# GD32F3x0 register map
File version: 1.0
CPU: CM4 r2p1, little endian, MPU, no FPU, 4 interrupt priority bits
Registers are 32-bit, read-write, reset 0x0 unless marked. A register's access mark holds for its fields unless they carry their own. Offsets are from the block's base; [hi:lo] are bit positions.

## CEC — HDMI-CEC controller
Base 0x40007800
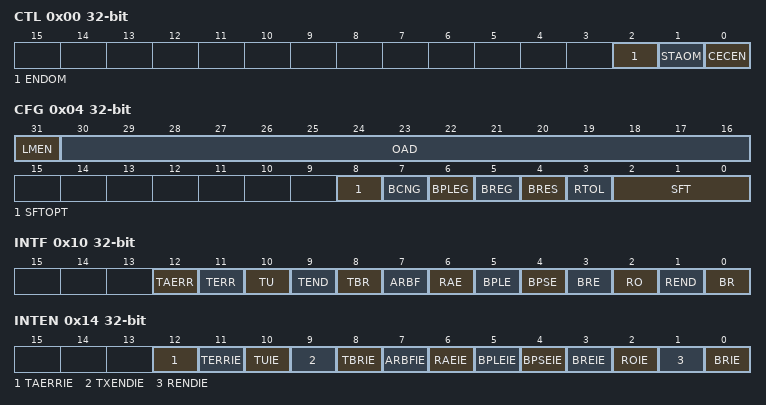
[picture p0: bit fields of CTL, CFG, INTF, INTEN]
0x00 CTL — control register
  [2] ENDOM — ENDOM bit value in the next frame in TX mode
  [1] STAOM — Start of sending a message
  [0] CECEN — CEC controller Enable
0x04 CFG — Configuration register
  [31] LMEN — Listen mode enable
  [30:16] OAD — Own Address
  [8] SFTOPT — The SFT start option bit
  [7] BCNG — Do not generate Error-bit in broadcast message
  [6] BPLEG — Generate an Error-bit when detected BPLE in singlecast
  [5] BREG — Generate an Error-bit when detected BRE in singlecast
  [4] BRES — Whether stop receive message when detected BRE
  [3] RTOL — Reception bit timing tolerance
  [2:0] SFT — Signal Free Time
0x08 TDATA wo — Transmit data register
  [7:0] TDATA — Tx Data register
0x0C RDATA ro — Rx Data Register
  [7:0] RDATA — CEC Rx Data Register
0x10 INTF — Interrupt Flag Register
  [12] TAERR — Tx-Missing acknowledge error
  [11] TERR — Tx-Error
  [10] TU — Tx-Buffer Underrun
  [9] TEND — End of Transmission
  [8] TBR — Tx-Byte Request
  [7] ARBF — Arbitration fail
  [6] RAE — Rx Acknowledge error
  [5] BPLE — Bit Period Long Error
  [4] BPSE — Bit period short error
  [3] BRE — Bit rising error
  [2] RO — Rx-Overrun
  [1] REND — End Of Reception
  [0] BR — Rx-Byte Received
0x14 INTEN — interrupt enable register
  [12] TAERRIE — Tx-Missing Acknowledge Error Interrupt Enable
  [11] TERRIE — Tx-Error Interrupt Enable
  [10] TUIE — Tx-Underrun interrupt enable
  [9] TXENDIE — Tx-End of message interrupt enable
  [8] TBRIE — Tx-Byte Request Interrupt Enable
  [7] ARBFIE — ARBF Interrupt Enable
  [6] RAEIE — Rx-Missing Acknowledge Error Interrupt Enable
  [5] BPLEIE — Long Bit Period Error Interrupt Enable
  [4] BPSEIE — Short Bit Period Error Interrupt Enable
  [3] BREIE — Bit Rising Error Interrupt Enable
  [2] ROIE — Rx-Buffer Overrun Interrupt Enable
  [1] RENDIE — End Of Reception Interrupt Enable
  [0] BRIE — Rx-Byte Received Interrupt Enable

## CMP — Comparator
Base 0x4001001C
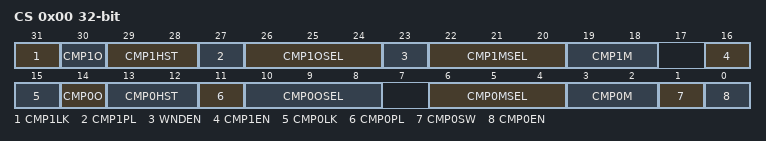
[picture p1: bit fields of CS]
0x00 CS access per field — control and status register
  [31] CMP1LK rw — Comparator 1 lock
  [30] CMP1O ro — Comparator 1 output
  [29:28] CMP1HST rw — Comparator 1 hysteresis
  [27] CMP1PL rw — Comparator 1 output polarity
  [26:24] CMP1OSEL rw — Comparator 1 output selection
  [23] WNDEN rw — Window mode enable
  [22:20] CMP1MSEL rw — Comparator 1 inverting input selection
  [19:18] CMP1M rw — Comparator 1 mode
  [16] CMP1EN rw — Comparator 1 enable
  [15] CMP0LK rw — Comparator 0 lock
  [14] CMP0O ro — Comparator 0 output
  [13:12] CMP0HST rw — Comparator 0 hysteresis
  [11] CMP0PL rw — Polarity of comparator 0 output
  [10:8] CMP0OSEL rw — Comparator 0 output selection
  [6:4] CMP0MSEL rw — Comparator 0 input selection
  [3:2] CMP0M rw — Comparator 0 mode
  [1] CMP0SW rw — Comparator 0 switch
  [0] CMP0EN rw — Comparator 0 enable

## CRC — cyclic redundancy check calculation unit
Base 0x40023000
0x00 DATA reset 0xFFFFFFFF
  [31:0] DATA — CRC calculation result bits
0x04 FDATA — Free data register
  [7:0] FDATA — General-purpose 8-bit data register bits
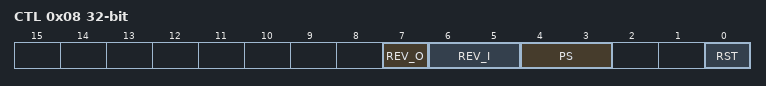
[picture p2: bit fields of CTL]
0x08 CTL — Control register
  [7] REV_O — Reverse output data
  [6:5] REV_I — Reverse input data
  [4:3] PS — Size of polynomial
  [0] RST — reset bit
0x10 IDATA reset 0xFFFFFFFF — Initialization Data Register
  [31:0] IDATA — CRC calculation initial value
0x14 POLY reset 0x4C11DB7 — Polynomial register
  [31:0] POLY — User configurable polynomial value

## CTC — Clock trim controller
Base 0x4000C800
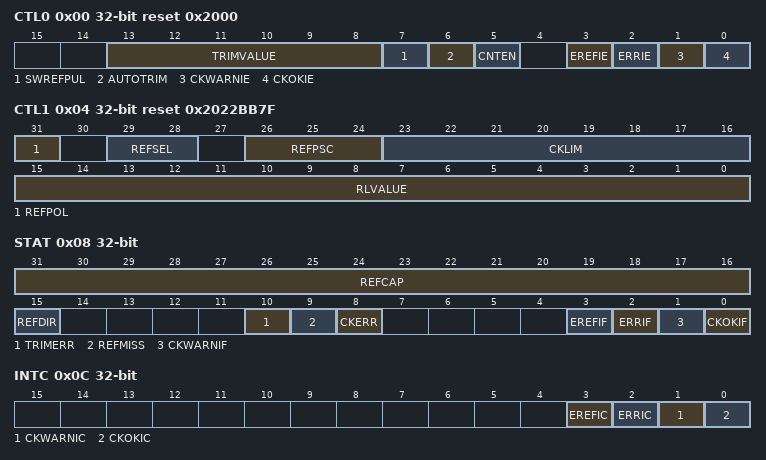
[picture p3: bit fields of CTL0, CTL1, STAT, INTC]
0x00 CTL0 reset 0x2000 — Control Register 0
  [13:8] TRIMVALUE — IRC48M trim value
  [7] SWREFPUL — Software reference source sync pulse
  [6] AUTOTRIM — Hardware automatically trim mode
  [5] CNTEN — CTC counter enable
  [3] EREFIE — EREFIF interrupt enable
  [2] ERRIE — Error (ERRIF) interrupt enable
  [1] CKWARNIE — Clock trim warning (CKWARNIF) interrupt enable
  [0] CKOKIE — Clock trim OK (CKOKIF) interrupt enable
0x04 CTL1 reset 0x2022BB7F — Control Register 1
  [31] REFPOL — Reference signal source polarity
  [29:28] REFSEL — Reference signal source selection
  [26:24] REFPSC — Reference signal source prescaler
  [23:16] CKLIM — Clock trim base limit value
  [15:0] RLVALUE — CTC counter reload value
0x08 STAT ro — Status Register
  [31:16] REFCAP — CTC counter capture when reference sync pulse
  [15] REFDIR — CTC trim counter direction when reference sync pulse
  [10] TRIMERR — Trim value error bit
  [9] REFMISS — Reference sync pulse miss
  [8] CKERR — Clock trim error bit
  [3] EREFIF — Expect reference interrupt flag
  [2] ERRIF — Error interrupt flag
  [1] CKWARNIF — Clock trim warning interrupt flag
  [0] CKOKIF — Clock trim OK interrupt flag
0x0C INTC wo — Interrupt clear Register
  [3] EREFIC — EREFIF interrupt clear bit
  [2] ERRIC — ERRIF interrupt clear bit
  [1] CKWARNIC — CKWARNIF interrupt clear bit
  [0] CKOKIC — CKOKIF interrupt clear bit
